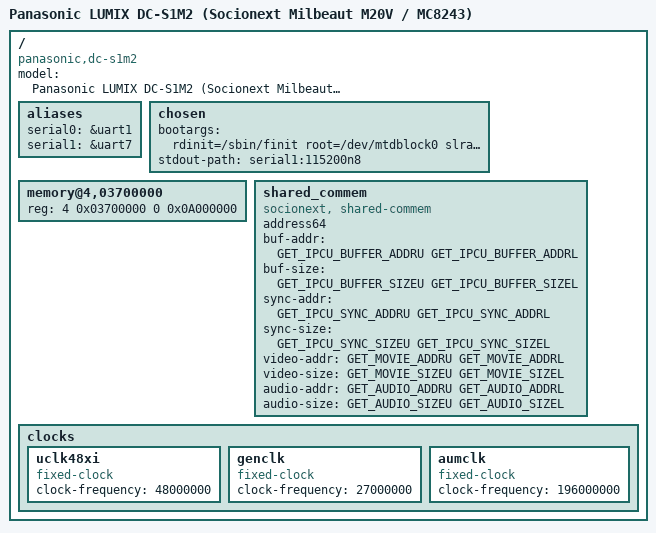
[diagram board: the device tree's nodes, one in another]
// SPDX-License-Identifier: GPL-2.0
/*
 * Reconstructed Board-level Device Tree for Panasonic LUMIX S1M2 (DC-S1M2)
 *
 * Board Target: Panasonic LUMIX S1M2 (MC8243 Platform)
 * SoC: Socionext Milbeaut M20V (Karine / SC2006A / MC8241)
 * Kernel: Linux 4.19.124-karine-arm64
 */

/dts-v1/;

#include "s1m2-socionext-m20v.dtsi"
#include "s1m2-m20v-rtos.h"
#include "s1m2-m20v-gpio.h"

/ {
	model = "Panasonic LUMIX DC-S1M2 (Socionext Milbeaut M20V / MC8243)";
	compatible = "panasonic,dc-s1m2", "socionext,pvc04v-MC8241-2ND", "socionext,sc2006";

	aliases {
		serial0 = &uart1;
		serial1 = &uart7;
	};

	chosen {
		bootargs = "rdinit=/sbin/finit root=/dev/mtdblock0 slram=slram0,0x4012A0000,+0x00400000,slram1,0x4016A0000,+0x02060000 rootwait nr_cpu=1 nokaslr loglevel=0 console=null";
		stdout-path = "serial1:115200n8";
	};

	/* Linux Kernel Execution RAM: Exactly 160MB at 0x4_0370_0000 */
	memory@4,03700000 {
		device_type = "memory";
		reg = <4 0x03700000 0 0x0A000000>;
	};

	/* Shared Memory Table Descriptor between RTOS and Linux */
	shared_commem: shared_commem {
		compatible = "socionext, shared-commem";
		address64;
		buf-addr = <GET_IPCU_BUFFER_ADDRU GET_IPCU_BUFFER_ADDRL>;
		buf-size = <GET_IPCU_BUFFER_SIZEU GET_IPCU_BUFFER_SIZEL>;
		sync-addr = <GET_IPCU_SYNC_ADDRU GET_IPCU_SYNC_ADDRL>;
		sync-size = <GET_IPCU_SYNC_SIZEU GET_IPCU_SYNC_SIZEL>;
		video-addr = <GET_MOVIE_ADDRU GET_MOVIE_ADDRL>;
		video-size = <GET_MOVIE_SIZEU GET_MOVIE_SIZEL>;
		audio-addr = <GET_AUDIO_ADDRU GET_AUDIO_ADDRL>;
		audio-size = <GET_AUDIO_SIZEU GET_AUDIO_SIZEL>;
		status = "okay";
	};

	clocks {
		uclk48xi: uclk48xi {
			compatible = "fixed-clock";
			#clock-cells = <0>;
			clock-frequency = <48000000>;
		};

		genclk: genclk {
			compatible = "fixed-clock";
			#clock-cells = <0>;
			clock-frequency = <27000000>;
		};

		aumclk: aumclk {
			compatible = "fixed-clock";
			#clock-cells = <0>;
			clock-frequency = <196000000>;
		};
	};
};
